VERSION "created by canmatrix"

NS_ :

BS_:

BU_:

BO_ 38 Steering_RTD: 1 Vector__XXX
 SG_ RTD_CMD : 0|8@1+ (1.000000,0.000000) [0.000000|255.000000] "" Vector__XXX

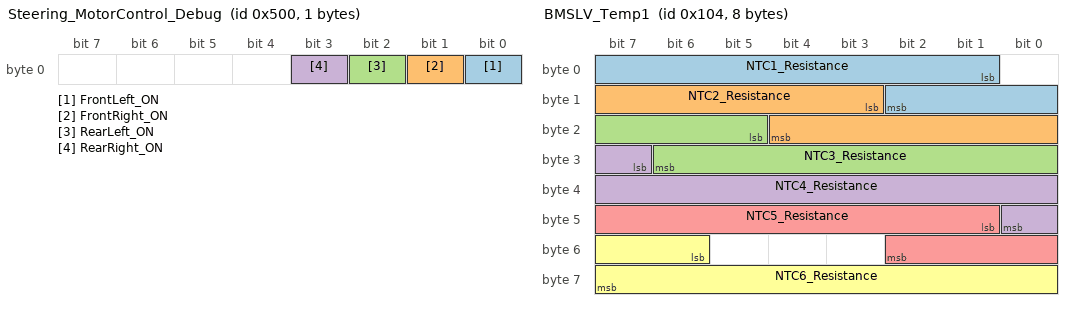
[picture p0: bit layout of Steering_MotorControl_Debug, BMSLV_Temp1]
BO_ 1280 Steering_MotorControl_Debug: 1 Vector__XXX
 SG_ FrontLeft_ON : 0|1@1- (1.000000,0.000000) [0.000000|1.000000] "" Vector__XXX
 SG_ FrontRight_ON : 1|1@1- (1.000000,0.000000) [0.000000|1.000000] "" Vector__XXX
 SG_ RearLeft_ON : 2|1@1- (1.000000,0.000000) [0.000000|1.000000] "" Vector__XXX
 SG_ RearRight_ON : 3|1@1- (1.000000,0.000000) [0.000000|1.000000] "" Vector__XXX

BO_ 260 BMSLV_Temp1: 8 Vector__XXX
 SG_ NTC1_Resistance : 1|10@1+ (31.250000,1000.000000) [0.000000|31968.750000] "" Vector__XXX
 SG_ NTC2_Resistance : 11|10@1+ (31.250000,1000.000000) [0.000000|31968.750000] "" Vector__XXX
 SG_ NTC3_Resistance : 21|10@1+ (31.250000,1000.000000) [0.000000|31968.750000] "" Vector__XXX
 SG_ NTC4_Resistance : 31|10@1+ (31.250000,1000.000000) [0.000000|31968.750000] "" Vector__XXX
 SG_ NTC5_Resistance : 41|10@1+ (31.250000,1000.000000) [0.000000|31968.750000] "" Vector__XXX
 SG_ NTC6_Resistance : 54|10@1+ (31.250000,1000.000000) [0.000000|31968.750000] "" Vector__XXX

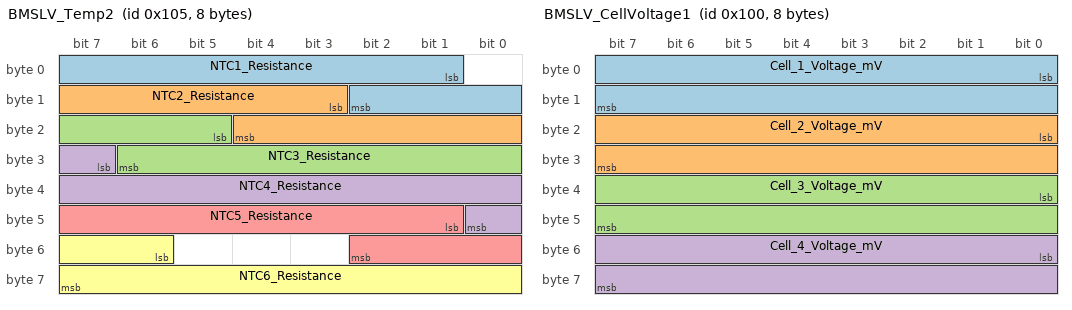
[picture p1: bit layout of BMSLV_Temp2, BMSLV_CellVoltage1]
BO_ 261 BMSLV_Temp2: 8 Vector__XXX
 SG_ NTC1_Resistance : 1|10@1+ (31.250000,1000.000000) [0.000000|31968.750000] "" Vector__XXX
 SG_ NTC2_Resistance : 11|10@1+ (31.250000,1000.000000) [0.000000|31968.750000] "" Vector__XXX
 SG_ NTC3_Resistance : 21|10@1+ (31.250000,1000.000000) [0.000000|31968.750000] "" Vector__XXX
 SG_ NTC4_Resistance : 31|10@1+ (31.250000,1000.000000) [0.000000|31968.750000] "" Vector__XXX
 SG_ NTC5_Resistance : 41|10@1+ (31.250000,1000.000000) [0.000000|31968.750000] "" Vector__XXX
 SG_ NTC6_Resistance : 54|10@1+ (31.250000,1000.000000) [0.000000|31968.750000] "" Vector__XXX

BO_ 256 BMSLV_CellVoltage1: 8 Vector__XXX
 SG_ Cell_1_Voltage_mV : 0|16@1+ (0.038000,2000.000000) [0.000000|2490.330000] "" Vector__XXX
 SG_ Cell_2_Voltage_mV : 16|16@1+ (0.038000,2000.000000) [0.000000|2490.330000] "" Vector__XXX
 SG_ Cell_3_Voltage_mV : 32|16@1+ (0.038000,2000.000000) [0.000000|2490.330000] "" Vector__XXX
 SG_ Cell_4_Voltage_mV : 48|16@1+ (0.038000,2000.000000) [0.000000|2490.330000] "" Vector__XXX

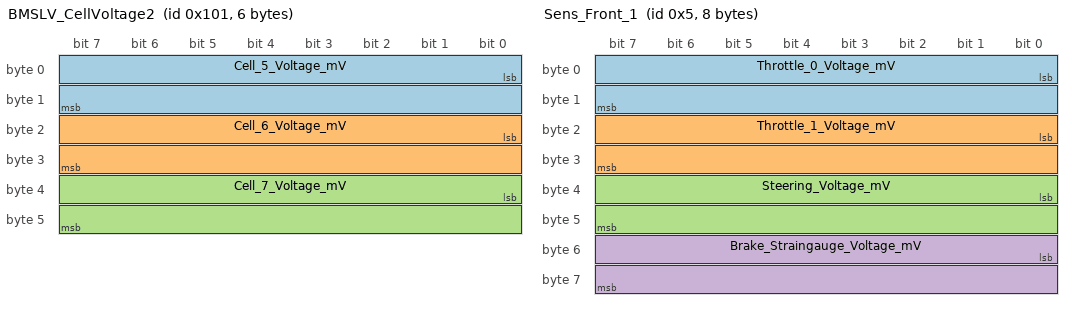
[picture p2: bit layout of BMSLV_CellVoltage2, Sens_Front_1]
BO_ 257 BMSLV_CellVoltage2: 6 Vector__XXX
 SG_ Cell_5_Voltage_mV : 0|16@1+ (0.038000,2000.000000) [0.000000|2490.330000] "" Vector__XXX
 SG_ Cell_6_Voltage_mV : 16|16@1+ (0.038000,2000.000000) [0.000000|2490.330000] "" Vector__XXX
 SG_ Cell_7_Voltage_mV : 32|16@1+ (1.000000,0.000000) [0.000000|65535.000000] "" Vector__XXX

BO_ 258 BMSLV_BatteryPackGeneral: 4 Vector__XXX
 SG_ Current_Sensor_Voltage : 0|16@1+ (0.076000,0.000000) [0.000000|4980.660000] "" Vector__XXX
 SG_ LV_Total_Voltage_mV : 16|16@1+ (0.267000,14000.000000) [0.000000|17497.845000] "" Vector__XXX

BO_ 259 BMSLV_Status: 2 Vector__XXX
 SG_ isRelayOpen : 0|1@1- (1.000000,0.000000) [0.000000|1.000000] "" Vector__XXX
 SG_ BMSLV_StatusMessage : 1|8@1+ (1.000000,0.000000) [0.000000|255.000000] "" Vector__XXX

BO_ 5 Sens_Front_1: 8 Vector__XXX
 SG_ Throttle_0_Voltage_mV : 0|16@1+ (1.000000,0.000000) [0.000000|65535.000000] "" Vector__XXX
 SG_ Throttle_1_Voltage_mV : 16|16@1+ (1.000000,0.000000) [0.000000|65535.000000] "" Vector__XXX
 SG_ Steering_Voltage_mV : 32|16@1+ (1.000000,0.000000) [0.000000|65535.000000] "" Vector__XXX
 SG_ Brake_Straingauge_Voltage_mV : 48|16@1+ (1.000000,0.000000) [0.000000|65535.000000] "" Vector__XXX

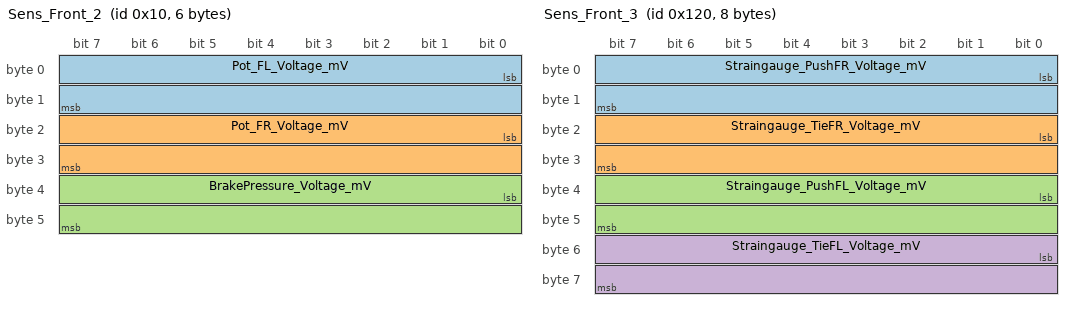
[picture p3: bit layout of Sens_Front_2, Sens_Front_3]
BO_ 16 Sens_Front_2: 6 Vector__XXX
 SG_ Pot_FL_Voltage_mV : 0|16@1+ (1.000000,0.000000) [0.000000|65535.000000] "" Vector__XXX
 SG_ Pot_FR_Voltage_mV : 16|16@1+ (1.000000,0.000000) [0.000000|65535.000000] "" Vector__XXX
 SG_ BrakePressure_Voltage_mV : 32|16@1+ (1.000000,0.000000) [0.000000|65535.000000] "" Vector__XXX

BO_ 288 Sens_Front_3: 8 Vector__XXX
 SG_ Straingauge_PushFR_Voltage_mV : 0|16@1+ (1.000000,0.000000) [0.000000|65535.000000] "" Vector__XXX
 SG_ Straingauge_TieFR_Voltage_mV : 16|16@1+ (1.000000,0.000000) [0.000000|65535.000000] "" Vector__XXX
 SG_ Straingauge_PushFL_Voltage_mV : 32|16@1+ (1.000000,0.000000) [0.000000|65535.000000] "" Vector__XXX
 SG_ Straingauge_TieFL_Voltage_mV : 48|16@1+ (1.000000,0.000000) [0.000000|65535.000000] "" Vector__XXX

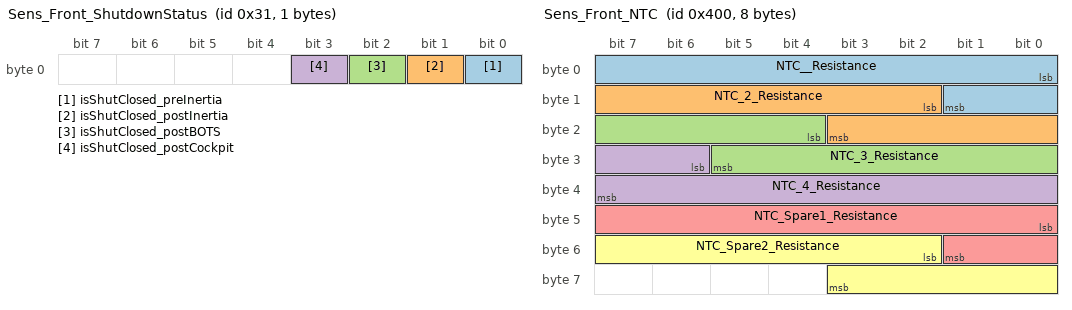
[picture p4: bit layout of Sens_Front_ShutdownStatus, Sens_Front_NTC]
BO_ 49 Sens_Front_ShutdownStatus: 1 Vector__XXX
 SG_ isShutClosed_preInertia : 0|1@1- (1.000000,0.000000) [0.000000|1.000000] "" Vector__XXX
 SG_ isShutClosed_postInertia : 1|1@1- (1.000000,0.000000) [0.000000|1.000000] "" Vector__XXX
 SG_ isShutClosed_postBOTS : 2|1@1- (1.000000,0.000000) [0.000000|1.000000] "" Vector__XXX
 SG_ isShutClosed_postCockpit : 3|1@1- (1.000000,0.000000) [0.000000|1.000000] "" Vector__XXX

BO_ 1024 Sens_Front_NTC: 8 Vector__XXX
 SG_ NTC__Resistance : 0|10@1+ (1.000000,0.000000) [0.000000|1023.000000] "" Vector__XXX
 SG_ NTC_2_Resistance : 10|10@1+ (1.000000,0.000000) [0.000000|1023.000000] "" Vector__XXX
 SG_ NTC_3_Resistance : 20|10@1+ (1.000000,0.000000) [0.000000|1023.000000] "" Vector__XXX
 SG_ NTC_4_Resistance : 30|10@1+ (1.000000,0.000000) [0.000000|1023.000000] "" Vector__XXX
 SG_ NTC_Spare1_Resistance : 40|10@1+ (1.000000,0.000000) [0.000000|1023.000000] "" Vector__XXX
 SG_ NTC_Spare2_Resistance : 50|10@1+ (1.000000,0.000000) [0.000000|1023.000000] "" Vector__XXX

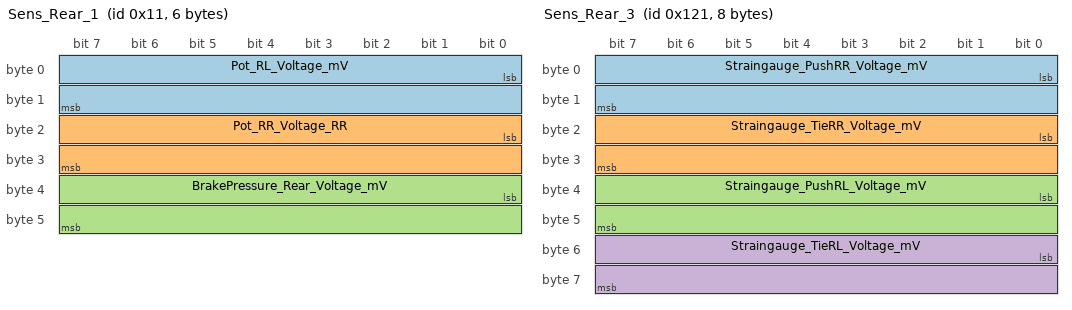
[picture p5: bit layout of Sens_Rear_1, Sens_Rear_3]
BO_ 17 Sens_Rear_1: 6 Vector__XXX
 SG_ Pot_RL_Voltage_mV : 0|16@1+ (1.000000,0.000000) [0.000000|65535.000000] "" Vector__XXX
 SG_ Pot_RR_Voltage_RR : 16|16@1+ (1.000000,0.000000) [0.000000|65535.000000] "" Vector__XXX
 SG_ BrakePressure_Rear_Voltage_mV : 32|16@1+ (1.000000,0.000000) [0.000000|65535.000000] "" Vector__XXX

BO_ 289 Sens_Rear_3: 8 Vector__XXX
 SG_ Straingauge_PushRR_Voltage_mV : 0|16@1+ (1.000000,0.000000) [0.000000|65535.000000] "" Vector__XXX
 SG_ Straingauge_TieRR_Voltage_mV : 16|16@1+ (1.000000,0.000000) [0.000000|65535.000000] "" Vector__XXX
 SG_ Straingauge_PushRL_Voltage_mV : 32|16@1+ (1.000000,0.000000) [0.000000|65535.000000] "" Vector__XXX
 SG_ Straingauge_TieRL_Voltage_mV : 48|16@1+ (1.000000,0.000000) [0.000000|65535.000000] "" Vector__XXX

BO_ 1026 Sens_Rear_2: 4 Vector__XXX
 SG_ CoolingPressure_DX_Voltage_mV : 0|16@1+ (1.000000,0.000000) [0.000000|65535.000000] "" Vector__XXX
 SG_ CoolingPressure_SX_Voltage_mV : 16|16@1+ (1.000000,0.000000) [0.000000|65535.000000] "" Vector__XXX

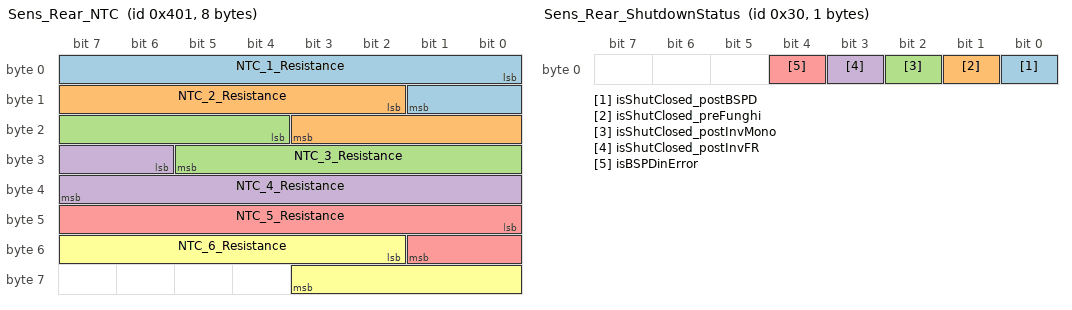
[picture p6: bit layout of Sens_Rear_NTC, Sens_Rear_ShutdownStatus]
BO_ 1025 Sens_Rear_NTC: 8 Vector__XXX
 SG_ NTC_1_Resistance : 0|10@1+ (1.000000,0.000000) [0.000000|1023.000000] "" Vector__XXX
 SG_ NTC_2_Resistance : 10|10@1+ (1.000000,0.000000) [0.000000|1023.000000] "" Vector__XXX
 SG_ NTC_3_Resistance : 20|10@1+ (1.000000,0.000000) [0.000000|1023.000000] "" Vector__XXX
 SG_ NTC_4_Resistance : 30|10@1+ (1.000000,0.000000) [0.000000|1023.000000] "" Vector__XXX
 SG_ NTC_5_Resistance : 40|10@1+ (1.000000,0.000000) [0.000000|1023.000000] "" Vector__XXX
 SG_ NTC_6_Resistance : 50|10@1+ (1.000000,0.000000) [0.000000|1023.000000] "" Vector__XXX

BO_ 48 Sens_Rear_ShutdownStatus: 1 Vector__XXX
 SG_ isShutClosed_postBSPD : 0|1@1- (1.000000,0.000000) [0.000000|1.000000] "" Vector__XXX
 SG_ isShutClosed_preFunghi : 1|1@1- (1.000000,0.000000) [0.000000|1.000000] "" Vector__XXX
 SG_ isShutClosed_postInvMono : 2|1@1- (1.000000,0.000000) [0.000000|1.000000] "" Vector__XXX
 SG_ isShutClosed_postInvFR : 3|1@1- (1.000000,0.000000) [0.000000|1.000000] "" Vector__XXX
 SG_ isBSPDinError : 4|1@1- (1.000000,0.000000) [0.000000|1.000000] "" Vector__XXX

BO_ 7 TLB_Battery_TSALStatus: 4 Vector__XXX
 SG_ IntentionalState_AIRPos : 8|1@1- (1.000000,0.000000) [0.000000|1.000000] "" Vector__XXX
 SG_ IntentionalState_AIRNeg : 9|1@1- (1.000000,0.000000) [0.000000|1.000000] "" Vector__XXX
 SG_ IntentionalState_RelayPrecharge : 10|1@1- (1.000000,0.000000) [0.000000|1.000000] "" Vector__XXX
 SG_ TSAL_isAIRPosClosed : 1|1@1- (1.000000,0.000000) [0.000000|1.000000] "" Vector__XXX
 SG_ TSAL_IsAIRNegClosed : 2|1@1- (1.000000,0.000000) [0.000000|1.000000] "" Vector__XXX
 SG_ TSAL_IsRelayPrechargeClosed : 3|1@1- (1.000000,0.000000) [0.000000|1.000000] "" Vector__XXX
 SG_ SCS_Short2GND_AirPos : 16|1@1- (1.000000,0.000000) [0.000000|1.000000] "" Vector__XXX
 SG_ SCS_Short2GND_AirNeg : 17|1@1- (1.000000,0.000000) [0.000000|1.000000] "" Vector__XXX
 SG_ TSAL_isDCBusOver60V : 4|1@1- (1.000000,0.000000) [0.000000|1.000000] "" Vector__XXX
 SG_ TSAL_isGreenON : 0|1@1- (1.000000,0.000000) [0.000000|1.000000] "" Vector__XXX
 SG_ Implausibility_isAnyImp_Present : 24|1@1- (1.000000,0.000000) [0.000000|1.000000] "" Vector__XXX
 SG_ Implausibility_isAIRPosImp_Prese : 25|1@1- (1.000000,0.000000) [0.000000|1.000000] "" Vector__XXX
 SG_ Implausibility_isAIRNegImp_Prese : 26|1@1- (1.000000,0.000000) [0.000000|1.000000] "" Vector__XXX
 SG_ Implausibility_isAnyImp_Latched : 29|1@1- (1.000000,0.000000) [0.000000|1.000000] "" Vector__XXX
 SG_ Implausibility_isRelayPrechargeI : 27|1@1- (1.000000,0.000000) [0.000000|1.000000] "" Vector__XXX
 SG_ Implausibility_isDCBusVoltageImp : 28|1@1- (1.000000,0.000000) [0.000000|1.000000] "" Vector__XXX
 SG_ SCS_isAnyShort2GND_Present : 19|1@1- (1.000000,0.000000) [0.000000|1.000000] "" Vector__XXX

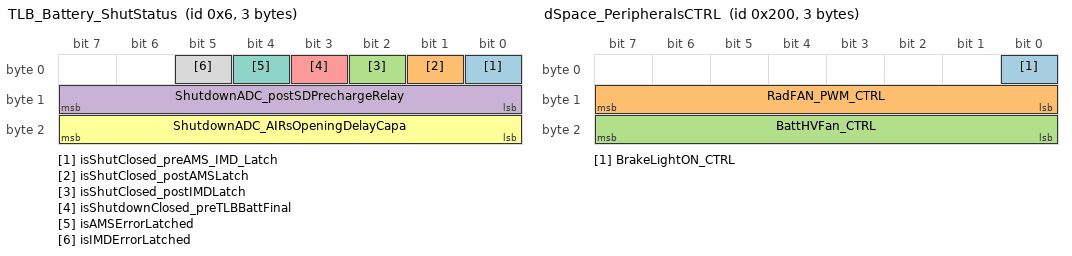
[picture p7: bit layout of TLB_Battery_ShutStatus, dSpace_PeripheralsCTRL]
BO_ 6 TLB_Battery_ShutStatus: 3 Vector__XXX
 SG_ isShutClosed_preAMS_IMD_Latch : 0|1@1- (1.000000,0.000000) [0.000000|1.000000] "" Vector__XXX
 SG_ isShutClosed_postAMSLatch : 1|1@1- (1.000000,0.000000) [0.000000|1.000000] "" Vector__XXX
 SG_ isShutClosed_postIMDLatch : 2|1@1- (1.000000,0.000000) [0.000000|1.000000] "" Vector__XXX
 SG_ ShutdownADC_postSDPrechargeRelay : 8|8@1+ (1.000000,0.000000) [0.000000|255.000000] "" Vector__XXX
 SG_ isShutdownClosed_preTLBBattFinal : 3|1@1- (1.000000,0.000000) [0.000000|1.000000] "" Vector__XXX
 SG_ ShutdownADC_AIRsOpeningDelayCapa : 16|8@1+ (1.000000,0.000000) [0.000000|255.000000] "" Vector__XXX
 SG_ isAMSErrorLatched : 4|1@1- (1.000000,0.000000) [0.000000|1.000000] "" Vector__XXX
 SG_ isIMDErrorLatched : 5|1@1- (1.000000,0.000000) [0.000000|1.000000] "" Vector__XXX

BO_ 512 dSpace_PeripheralsCTRL: 3 Vector__XXX
 SG_ BrakeLightON_CTRL : 0|1@1- (1.000000,0.000000) [0.000000|1.000000] "" Vector__XXX
 SG_ RadFAN_PWM_CTRL : 8|8@1+ (1.000000,0.000000) [0.000000|255.000000] "" Vector__XXX
 SG_ BattHVFan_CTRL : 16|8@1+ (1.000000,0.000000) [0.000000|255.000000] "" Vector__XXX

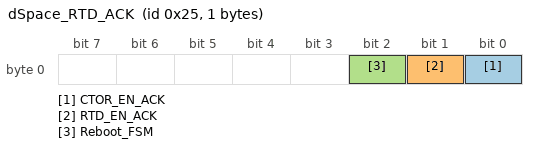
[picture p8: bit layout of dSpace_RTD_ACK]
BO_ 37 dSpace_RTD_ACK: 1 Vector__XXX
 SG_ CTOR_EN_ACK : 0|1@1- (1.000000,0.000000) [0.000000|1.000000] "" Vector__XXX
 SG_ RTD_EN_ACK : 1|1@1- (1.000000,0.000000) [0.000000|1.000000] "" Vector__XXX
 SG_ Reboot_FSM : 2|1@1- (1.000000,0.000000) [0.000000|1.000000] "" Vector__XXX

BA_DEF_ SG_ "SystemSignalLongSymbol" STRING;

BA_ "SystemSignalLongSymbol" SG_ 7 Implausibility_isAIRPosImp_Prese "Implausibility_isAIRPosImp_Present";
BA_ "SystemSignalLongSymbol" SG_ 7 Implausibility_isAIRNegImp_Prese "Implausibility_isAIRNegImp_Present";
BA_ "SystemSignalLongSymbol" SG_ 7 Implausibility_isRelayPrechargeI "Implausibility_isRelayPrechargeImp_Present";
BA_ "SystemSignalLongSymbol" SG_ 7 Implausibility_isDCBusVoltageImp "Implausibility_isDCBusVoltageImp_Present";
BA_ "SystemSignalLongSymbol" SG_ 6 ShutdownADC_AIRsOpeningDelayCapa "ShutdownADC_AIRsOpeningDelayCapacitors";
